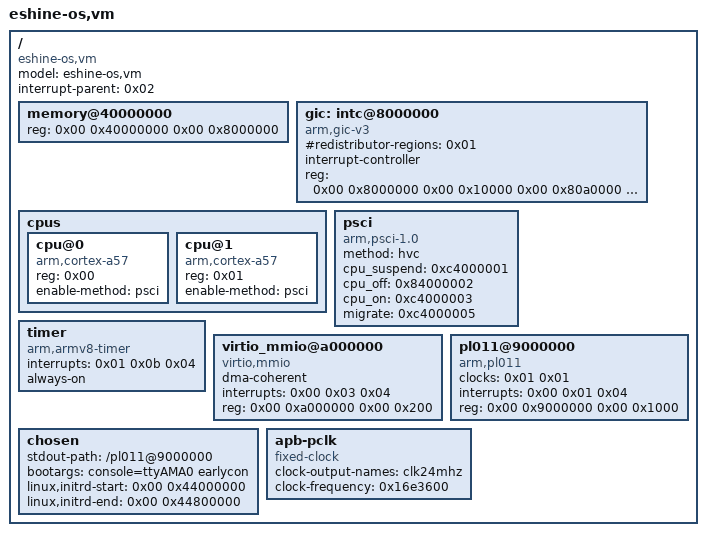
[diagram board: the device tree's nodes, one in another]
/* SPDX-License-Identifier: Apache-2.0 */
/* Copyright (c) 2026 Julian Chu */
/*
 * eshine-os Linux guest 设备树(第十四站:bring-up)
 *
 * 与 eshine-vm.dts 同源(同一 QEMU dumpdtb 裁剪原则,同一诚实清单),
 * 首次 per-VM 真分歧(站 11 欠账兑现):
 *   - memory:16MB -> 128MB(槽 2 几何:RAM 0x40000000/128MB)
 *   - chosen:增 bootargs —— console=ttyAMA0 + earlycon(裸关键字走
 *     DT stdout-path 探测,pl011 earlycon 不逐寄存器配置)
 * 站19D:guest SMP 面——cpu@1 + enable-method=psci + psci 节点 +
 *   GICR 双帧窗口(0x40000)。vm0/vm1 仍单核视角(eshine-vm.dts
 *   不动,各自 1 vCPU 的诚实);本树仅 vm2(双 vCPU)。
 * 已知限制:两 dts 并存有漂移风险;分歧再长大时上运行时 patch。
 */
/dts-v1/;

/ {
	model = "eshine-os,vm";
	#size-cells = <0x02>;
	#address-cells = <0x02>;
	compatible = "eshine-os,vm";
	interrupt-parent = <0x02>;

	memory@40000000 {
		reg = <0x00 0x40000000 0x00 0x8000000>;	/* 128MB(槽 2 几何) */
		device_type = "memory";
	};

	gic: intc@8000000 {
		compatible = "arm,gic-v3";
		#redistributor-regions = <0x01>;
		#interrupt-cells = <0x03>;
		interrupt-controller;
		reg = <0x00 0x8000000 0x00 0x10000	/* GICD */
		       0x00 0x80a0000 0x00 0x40000>;	/* GICR:双 vCPU 双帧
						 * (每帧 RD 0x10000+SGI 0x10000,
						 * 帧号=off>>17,站19D) */
		phandle = <0x02>;
	};

	cpus {
		#size-cells = <0x00>;
		#address-cells = <0x01>;

		cpu@0 {
			reg = <0x00>;
			enable-method = "psci";	/* 站19D:次核经 PSCI SMC 上线 */
			compatible = "arm,cortex-a57";
			device_type = "cpu";
		};

		cpu@1 {
			reg = <0x01>;
			enable-method = "psci";
			compatible = "arm,cortex-a57";
			device_type = "cpu";
		};
	};

	psci {
		compatible = "arm,psci-1.0\0arm,psci-0.2\0arm,psci";	/* QEMU -smp 3 dumpdtb 原形 */
		method = "hvc";			/* 站19D 探针定谳:QEMU 机器级 PSCI 截获
						 * EL1 的 SMC(TCG conduit 优先于 EL2 陷入,
						 * 零 [PSCI] 打印实证),HVC 才到我们的
						 * EL2(EC 0x16 imm#0 分发)——站18 设计
						 * 预留的兜底路径启用 */
		cpu_suspend = <0xc4000001>;	/* standby 空转返回 0(power_level>0 残余) */
		cpu_off = <0x84000002>;		/* 返回 -1(不支持,Linux 热插拔用不到) */
		cpu_on = <0xc4000003>;		/* 置 vm2.vcpus[1] 帧 + poke pcpu2 */
		migrate = <0xc4000005>;		/* 返回 -1(不支持) */
	};

	timer {
		interrupts = <0x01 0x0b 0x04>;	/* 只留虚拟定时器 PPI 11 = INTID 27 */
		interrupt-names = "virt";	/* 稀疏接线声明:Linux 按名映射到 virt 槽
						 (按 index 会错落 sec-phys 槽) */
		always-on;
		compatible = "arm,armv8-timer";
	};

	virtio_mmio@a000000 {
		dma-coherent;
		interrupts = <0x00 0x03 0x04>;	/* 补丁:SPI 16 -> SPI 3 = INTID 35 */
		reg = <0x00 0xa000000 0x00 0x200>;
		compatible = "virtio,mmio";
	};

	pl011@9000000 {
		clock-names = "uartclk\0apb_pclk";
		clocks = <0x01 0x01>;
		interrupts = <0x00 0x01 0x04>;	/* SPI 1 = INTID 33,vuart RX */
		reg = <0x00 0x9000000 0x00 0x1000>;
		compatible = "arm,pl011\0arm,primecell";
	};

	chosen {
		stdout-path = "/pl011@9000000";
		bootargs = "console=ttyAMA0 earlycon";   /* initramfs /init 默认接管 */
		/* 站十五:initramfs 定长 8MB 槽(loader 同构:QEMU 直载宿主
		 * 0x5C000000 = IPA 0x44000000 经 stage-2 非恒等映射);cpio
		 * 尾零合法 padding,常量属性零运行时 patch。槽宽与
		 * scripts/build-initramfs.sh 的 SLOT 绑死。 */
		linux,initrd-start = <0x00 0x44000000>;
		linux,initrd-end = <0x00 0x44800000>;
	};

	apb-pclk {
		phandle = <0x01>;
		clock-output-names = "clk24mhz";
		clock-frequency = <0x16e3600>;
		#clock-cells = <0x00>;
		compatible = "fixed-clock";
	};
};
